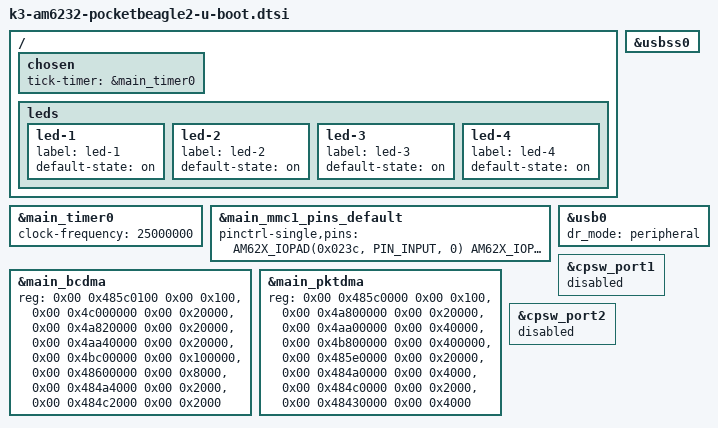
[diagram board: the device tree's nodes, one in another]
// SPDX-License-Identifier: GPL-2.0-only OR MIT
/*
 * https://www.beagleboard.org/boards/pocketbeagle-2
 *
 * Copyright (C) 2024 Texas Instruments Incorporated - https://www.ti.com/
 * Copyright (C) 2024 Robert Nelson, BeagleBoard.org Foundation
 */

#include "k3-am6232-pocketbeagle2-binman.dtsi"

/ {
	chosen {
		tick-timer = &main_timer0;
	};

	/* Keep the LEDs on by default to indicate life */
	leds {
		led-1 {
			label = "led-1";
			default-state = "on";
		};

		led-2 {
			label = "led-2";
			default-state = "on";
		};

		led-3 {
			label = "led-3";
			default-state = "on";
		};

		led-4 {
			label = "led-4";
			default-state = "on";
		};
	};
};

&main_timer0 {
	clock-frequency = <25000000>;
};

&main_mmc1_pins_default {
	/* Force to use SDCD card detect pin */
	pinctrl-single,pins = <
		AM62X_IOPAD(0x023c, PIN_INPUT, 0) /* (A21/C18) MMC1_CMD */
		AM62X_IOPAD(0x0234, PIN_INPUT, 0) /* (B22/A20) MMC1_CLK */
		AM62X_IOPAD(0x0230, PIN_INPUT, 0) /* (A22/A19) MMC1_DAT0 */
		AM62X_IOPAD(0x022c, PIN_INPUT, 0) /* (B21/B19) MMC1_DAT1 */
		AM62X_IOPAD(0x0228, PIN_INPUT, 0) /* (C21/B20) MMC1_DAT2 */
		AM62X_IOPAD(0x0224, PIN_INPUT, 0) /* (D22/C19) MMC1_DAT3 */
		AM62X_IOPAD(0x0240, PIN_INPUT, 0) /* (D17/C15) MMC1_SDCD */
	>;
};

&usbss0 {
	bootph-all;
};

&usb0 {
	dr_mode = "peripheral";
	bootph-all;
};

&main_bcdma {
	reg = <0x00 0x485c0100 0x00 0x100>,
	      <0x00 0x4c000000 0x00 0x20000>,
	      <0x00 0x4a820000 0x00 0x20000>,
	      <0x00 0x4aa40000 0x00 0x20000>,
	      <0x00 0x4bc00000 0x00 0x100000>,
	      <0x00 0x48600000 0x00 0x8000>,
	      <0x00 0x484a4000 0x00 0x2000>,
	      <0x00 0x484c2000 0x00 0x2000>;
	reg-names = "gcfg", "bchanrt", "rchanrt", "tchanrt", "ringrt",
		    "cfg", "tchan", "rchan";
};

&main_pktdma {
	reg = <0x00 0x485c0000 0x00 0x100>,
	      <0x00 0x4a800000 0x00 0x20000>,
	      <0x00 0x4aa00000 0x00 0x40000>,
	      <0x00 0x4b800000 0x00 0x400000>,
	      <0x00 0x485e0000 0x00 0x20000>,
	      <0x00 0x484a0000 0x00 0x4000>,
	      <0x00 0x484c0000 0x00 0x2000>,
	      <0x00 0x48430000 0x00 0x4000>;
	reg-names = "gcfg", "rchanrt", "tchanrt", "ringrt", "cfg",
		    "tchan", "rchan", "rflow";
	bootph-all;
};

&cpsw_port1 {
	status = "disabled";
};

&cpsw_port2 {
	status = "disabled";
};
